# AT32F415 register map
Vendor: Keil; Series: AT32F415; File version: 1.0
CPU: CM4 r0p1, little endian, no MPU, FPU, 4 interrupt priority bits
Registers are 32-bit, read-write, reset 0x0 unless marked. A register's access mark holds for its fields unless they carry their own. Offsets are from the block's base; [hi:lo] are bit positions; {n}, {i} and the like mark numbered series; 'fields as' and 'values as' point back to an identical list.

## PWC — Power control
Base 0x40007000
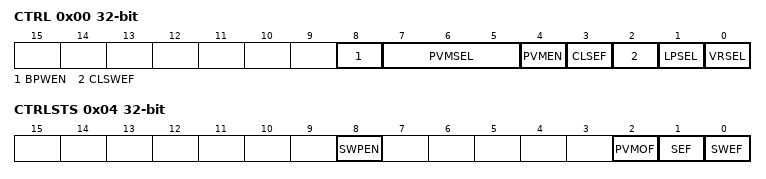
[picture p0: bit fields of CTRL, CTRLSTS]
0x00 CTRL — Power control register (PWC_CTRL)
  [8] BPWEN — Battery powered domain write enable
  [7:5] PVMSEL — Power voltage monitoring boundary select
  [4] PVMEN — Power voltage monitoring enable
  [3] CLSEF — Clear SEF flag
  [2] CLSWEF — Clear SWEF flag
  [1] LPSEL — Low power mode select when Cortex-M4F sleepdeep
  [0] VRSEL — Voltage regulator state select when deepsleep mode
0x04 CTRLSTS — Power control register (PWC_CTRLST)
  [8] SWPEN — Standby wake-up pin enable
  [2] PVMOF ro — Power voltage monitoring output flag
  [1] SEF ro — Standby mode entry flag
  [0] SWEF ro — Standby wake-up event flag

## GPIOA — General purpose IO
Base 0x40010800
Same registers: GPIOB 0x40010C00, GPIOC 0x40011000, GPIOD 0x40011400, GPIOF 0x40011C00
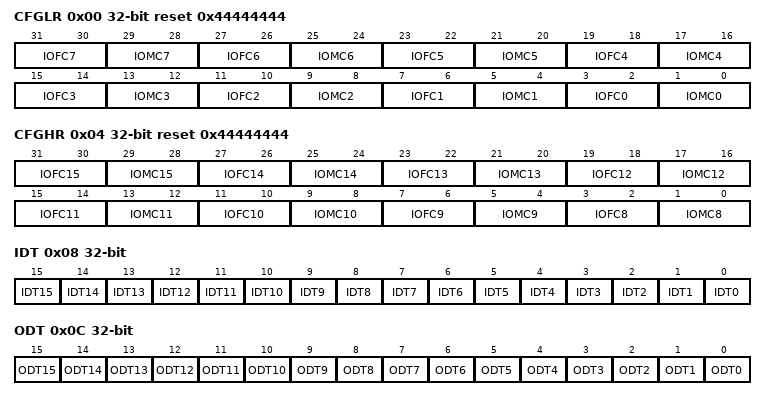
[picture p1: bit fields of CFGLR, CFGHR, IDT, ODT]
0x00 CFGLR reset 0x44444444 — GPIO function configurate low register
  [4n+3:4n+2] IOFC{n} (n=0..7) — Port n.{n} function configurate bits
    0=Analog input; 1=Floating input; 2=PullDownPullUp (Pull-down or pull-up input); 3=MuxOpenDrain (Multiplexed open drain)
  [4n+1:4n] IOMC{n} (n=0..7) — Port n.{n} mode configurate bits
    0=Input mode; 1=OutputLarge (Output mode, large sourcing/sinking strength); 2=Output mode, normal sourcing/sinking strength; 3=OutputMaximum (Output mode, maximum sourcing/sinking strength)
0x04 CFGHR reset 0x44444444 — GPIO function configurate high register
  [4n-29:4n-30] IOFC{n} (n=8..15) — Port n.{n} function configurate bits
    values as CFGLR.IOFC0
  [4n-31:4n-32] IOMC{n} (n=8..15) — Port n.{n} mode configurate bits
    values as CFGLR.IOMC0
0x08 IDT ro — Port input data register
  [n] IDT{n} (n=0..15) — Port input data
    0=Low (Input is logic low); 1=High (Input is logic high)
0x0C ODT — Port output data register
  [n] ODT{n} (n=0..15) — Port output data
    on read: 0=PullDown; 1=PullUp | on write: 0=Low (Set output to logic low); 1=High (Set output to logic high)
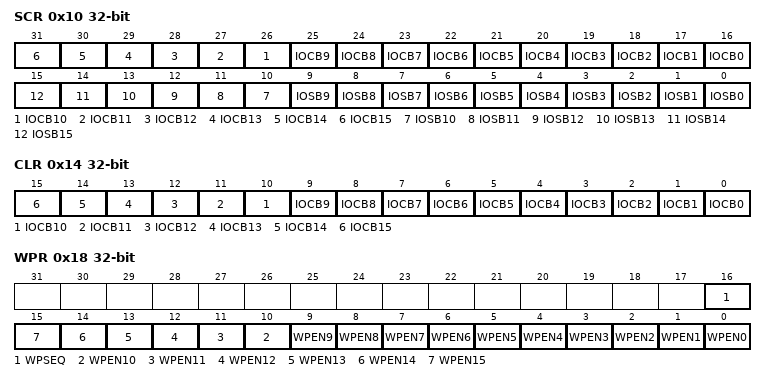
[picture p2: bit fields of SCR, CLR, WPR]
0x10 SCR wo — Port bit set/clear register
  [n+16] IOCB{n} (n=0..15) write-1-clears — Clear bit {n}
    1=Clear the corresponding ODT bit
  [n] IOSB{n} (n=0..15) write-1-sets — Set bit {n}
    1=Set (Set the corresponding ODT bit)
0x14 CLR wo — Port bit reset register
  [n] IOCB{n} (n=0..15) write-1-clears — Clear bit {n}
    1=Clear the corresponding ODT bit
0x18 WPR — Port write protect register
  [16] WPSEQ — Write protect sequence
    0=Clear; 1=Set
  [n] WPEN{n} (n=0..15) — Write protect enable {n}
    on read: 0=NotProtected (Port is not write protected); 1=Protected (Port is write protected) | on write: 0=NoProtect (No effect); 1=Protect (Write protect)

## EXINT
Base 0x40010400
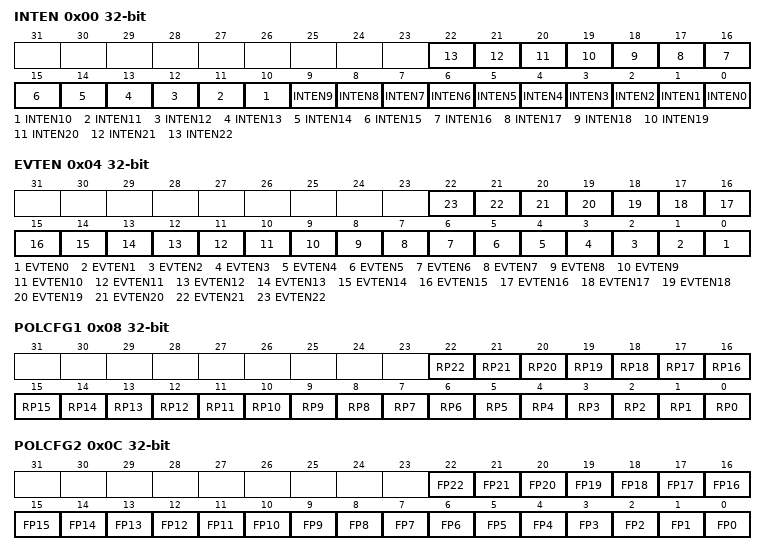
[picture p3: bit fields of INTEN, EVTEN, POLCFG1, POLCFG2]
0x00 INTEN — Interrupt enable register
  [n] INTEN{n} (n=0..22) — Interrupt enable or disable on line {n}
    on read: 0=Disabled (Interrupt request is disabled); 1=Enabled (Interrupt request is enabled) | on write: 0=Disable (Interrupt request disable); 1=Enable (Interrupt request enable)
0x04 EVTEN — Event enable register
  [n] EVTEN{n} (n=0..22) — Event enable or disable on line {n}
    on read: 0=Disabled (Event request is disabled); 1=Enabled (Event request is enabled) | on write: 0=Disable (Event request disable); 1=Enable (Event request enable)
0x08 POLCFG1 — Rising polarity configuration register
  [n] RP{n} (n=0..22) — Rising polarity configuration bit on line {n}
    on read: 0=Disabled (Rising trigger is disabled); 1=Enabled (Rising trigger is enabled) | on write: 0=Disable (Rising trigger disable); 1=Enable (Rising trigger enable)
0x0C POLCFG2 — Falling polarity configuration register
  [n] FP{n} (n=0..22) — Falling polarity configuration bit on line {n}
    on read: 0=Disabled (Falling polarity is disabled); 1=Enabled (Falling polarity is enabled) | on write: 0=Disable (Falling polarity disable); 1=Enable (Falling polarity enable)
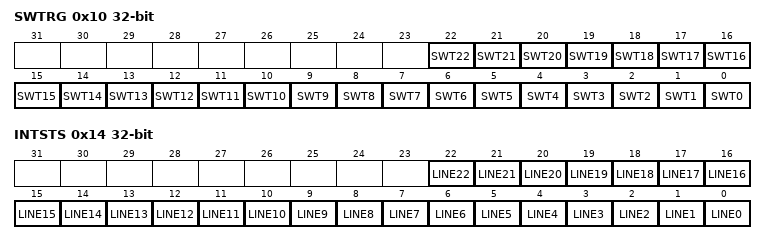
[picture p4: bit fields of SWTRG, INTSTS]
0x10 SWTRG — Software triggle register
  [n] SWT{n} (n=0..22) write-1-sets — Software trigger on line {n}
    on read: 0=NoTrigger (Default value); 1=Triggered (Software trigger generated) | on write: 1=Trigger (Generate trigger)
0x14 INTSTS — Interrupt status register
  [n] LINE{n} (n=0..22) write-1-clears — Line {n} status bit
    on read: 0=No interrupt occurred; 1=Interrupt occurred | on write: 1=Clear status flag
